# SKEAZ1284 register map
Vendor: Freescale Semiconductor, Inc.; Series: Kinetis_EA; File version: 1.6
CPU: CM0PLUS r0p0, little endian, no MPU, no FPU, VTOR, 2 interrupt priority bits
Registers are 8-bit, read-write, reset 0x0 unless marked. A register's access mark holds for its fields unless they carry their own. Offsets are from the block's base; [hi:lo] are bit positions.

## KBI0 — Keyboard interrupts
Base 0x40079000; register names take the prefix KBI0_
0x00 PE 32-bit — KBI Pin Enable Register
  [31:0] KBIPE — KBI Pin Enables
    0=Pin is not enabled as KBI interrupt; 1=Pin is enabled as KBI interrupt
0x04 ES 32-bit — KBI Edge Select Register
  [31:0] KBEDG — KBI Edge Selects
    0=Falling edge/low level; 1=Rising edge/high level
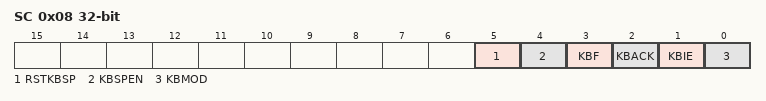
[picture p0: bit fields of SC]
0x08 SC 32-bit — KBI Status and Control Register
  [5] RSTKBSP — Reset KBI_SP registe
  [4] KBSPEN — Real KBI_SP register enable
    0=The real time value of Keyboard source pin to be read; 1=The latched value in KBxSP register while interrupt flag occur to be read
  [3] KBF ro — KBI Interrupt Flag
    0=KBI interrupt request not detected; 1=KBI interrupt request detected
  [2] KBACK wo — KBI Acknowledge
  [1] KBIE — KBI Interrupt Enable
    0=KBI interrupt not enabled; 1=KBI interrupt enabled
  [0] KBMOD — KBI Detection Mode
    0=Keyboard detects edges only; 1=Keyboard detects both edges and levels
0x0C SP 32-bit ro — KBI Source Pin Register
  [31:0] SP — KBI Source Pin

## KBI1 — Keyboard interrupts
Base 0x4007A000; register names take the prefix KBI1_
Registers as KBI0.

## PMC — Power management
Base 0x4007D000; register names take the prefix PMC_
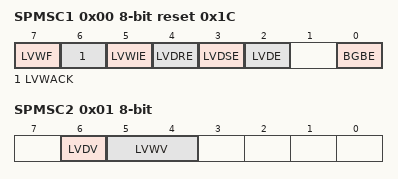
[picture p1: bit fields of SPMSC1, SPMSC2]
0x00 SPMSC1 reset 0x1C — System Power Management Status and Control 1 Register
  [7] LVWF ro — Low-Voltage Warning Flag
    0=Low-voltage warning is not present; 1=Low-voltage warning is present or was present
  [6] LVWACK wo — Low-Voltage Warning Acknowledge
  [5] LVWIE — Low-Voltage Warning Interrupt Enable
    0=Hardware interrupt is disabled (use polling); 1=Requests a hardware interrupt when LVWF = 1
  [4] LVDRE — Low-Voltage Detect Reset Enable
    0=LVD events do not generate hardware resets; 1=Forces an MCU reset when an enabled low-voltage detect event occurs
  [3] LVDSE — Low-Voltage Detect Stop Enable
    0=Low-voltage detect is disabled during Stop mode; 1=Low-voltage detect is enabled during Stop mode
  [2] LVDE — Low-Voltage Detect Enable
    0=LVD logic is disabled; 1=LVD logic is enabled
  [0] BGBE — Bandgap Buffer Enable
    0=Bandgap buffer is disabled; 1=Bandgap buffer is enabled
0x01 SPMSC2 — System Power Management Status and Control 2 Register
  [6] LVDV — Low-Voltage Detect Voltage Select
    0=Low trip point is selected (VLVD = VLVDL); 1=High trip point is selected (VLVD = VLVDH)
  [5:4] LVWV — Low-Voltage Warning Voltage Select
    0=Low trip point is selected (VLVW = VLVW1); 1=Middle 1 trip point is selected (VLVW = VLVW2); 2=Middle 2 trip point is selected (VLVW = VLVW3); 3=High trip point is selected (VLVW = VLVW4)

## GPIOA — General Purpose Input/Output
Base 0x400FF000; register names take the prefix GPIOA_
0x00 PDOR 32-bit — Port Data Output Register
  [31:0] PDO — Port Data Output
    0=Logic level 0 is driven on pin, provided pin is configured for general-purpose output; 1=Logic level 1 is driven on pin, provided pin is configured for general-purpose output
0x04 PSOR 32-bit wo — Port Set Output Register
  [31:0] PTSO — Port Set Output
    0=Corresponding bit in PDORn does not change; 1=Corresponding bit in PDORn is set to logic 1
0x08 PCOR 32-bit wo — Port Clear Output Register
  [31:0] PTCO — Port Clear Output
    0=Corresponding bit in PDORn does not change; 1=Corresponding bit in PDORn is cleared to logic 0
0x0C PTOR 32-bit wo — Port Toggle Output Register
  [31:0] PTTO — Port Toggle Output
    0=Corresponding bit in PDORn does not change; 1=Corresponding bit in PDORn is set to the inverse of its existing logic state
0x10 PDIR 32-bit ro — Port Data Input Register
  [31:0] PDI — Port Data Input
    0=Pin logic level is logic 0, or is not configured for use by digital function; 1=Pin logic level is logic 1
0x14 PDDR 32-bit — Port Data Direction Register
  [31:0] PDD — Port Data Direction
    0=Pin is configured as general-purpose input, for the GPIO function. The pin will be high-Z if the port input is disabled in GPIOx_PIDR register.; 1=Pin is configured as general-purpose output, for the GPIO function
0x18 PIDR 32-bit reset 0xFFFFFFFF — Port Input Disable Register
  [31:0] PID — Port Input Disable
    0=Pin is configured for General Purpose Input, provided the pin is configured for any digital function; 1=Pin is not configured as General Purpose Input.Corresponding Port Data Input Register bit will read zero

## GPIOB — General Purpose Input/Output
Base 0x400FF040; register names take the prefix GPIOB_
Registers as GPIOA.

## GPIOC — General Purpose Input/Output
Base 0x400FF080; register names take the prefix GPIOC_
Registers as GPIOA.

## FGPIOA — General Purpose Input/Output
Base 0xF8000000; register names take the prefix FGPIOA_
Registers as GPIOA; these are added or differ:
0x14 PDDR 32-bit — Port Data Direction Register
  [31:0] PDD — Port Data Direction
    0=Pin is configured as general-purpose input, for the GPIO function. The pin will be high-Z if the port input is disabled in FPIOx_PIDR register.; 1=Pin is configured as general-purpose output, for the GPIO function
0x18 PIDR 32-bit reset 0xFFFFFFFF — Port Input Disable Register
  [31:0] PID — Port Input Disable
    0=Pin is configured for General Purpose Input, provided the pin is configured for any digital function; 1=Pin is not configured as General Purpose Input. Corresponding Port Data Input Register bit will read zero.

## FGPIOB — General Purpose Input/Output
Base 0xF8000040; register names take the prefix FGPIOB_
Registers as FGPIOA.

## FGPIOC — General Purpose Input/Output
Base 0xF8000080; register names take the prefix FGPIOC_
Registers as FGPIOA.
